VERSION ""

NS_ :

BS_:

BU_: XXX

BO_ 1665 NEW_MSG_1: 8 XXX

BO_ 545 NEW_MSG_2: 8 XXX

BO_ 261 NEW_MSG_3: 8 XXX
 SG_ NEW_SIGNAL_1 : 15|2@0+ (1,0) [0|3] "" XXX
 SG_ NEW_SIGNAL_2 : 0|4@1+ (1,0) [0|15] "" XXX

BO_ 35 C3_Steering_Column_msg1: 8 XXX

BO_ 133 C2_Transmission_Control_msg1: 8 XXX

BO_ 55 C2_Transmission_Control_msg4: 8 XXX

BO_ 119 C8_Body_Control_msg62: 2 XXX

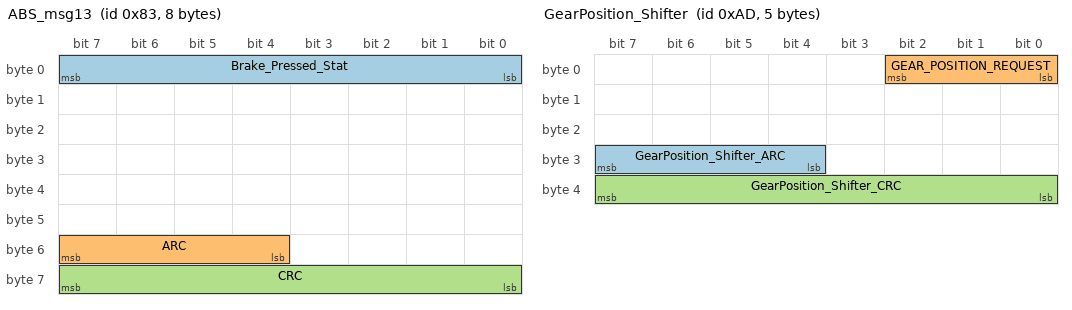
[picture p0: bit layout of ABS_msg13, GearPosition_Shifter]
BO_ 131 ABS_msg13: 8 XXX
 SG_ Brake_Pressed_Stat : 7|8@0+ (1,0) [0|255] "" XXX
 SG_ ARC : 55|4@0+ (1,0) [0|15] "" XXX
 SG_ CRC : 63|8@0+ (1,0) [0|255] "" XXX

BO_ 177 C3_Steering_Column_msg2: 3 XXX

BO_ 213 C5_Antilock_braking_system_msg4: 8 XXX

BO_ 808 C8_Body_Control_msg49: 8 XXX
 SG_ NEW_SIGNAL_1 : 5|20@0+ (1,0) [0|1048575] "" XXX

BO_ 173 GearPosition_Shifter: 5 XXX
 SG_ GearPosition_Shifter_ARC : 31|4@0+ (1,0) [0|15] "" XXX
 SG_ GEAR_POSITION_REQUEST : 0|3@1+ (1,0) [0|7] "" XXX
 SG_ GearPosition_Shifter_CRC : 32|8@1+ (1,0) [0|255] "" XXX

BO_ 1033 C6_Electronic_Shifter_msg1: 8 XXX

BO_ 973 C2_Cluster_msg1: 8 XXX

BO_ 906 C8_Body_Control_msg1: 8 XXX

BO_ 792 C3_Steering_Column_msg3: 8 XXX

BO_ 1059 C3_Steering_Column_msg4: 8 XXX

BO_ 938 C2_Cluster_msg2: 8 XXX

BO_ 673 C2_Cluster_msg3: 8 XXX

BO_ 635 C2_Cluster_msg4: 8 XXX

BO_ 939 C2_Cluster_msg5: 8 XXX

BO_ 634 C2_Cluster_msg6: 8 XXX

BO_ 940 C2_Cluster_msg7: 8 XXX

BO_ 941 C2_Cluster_msg8: 8 XXX

BO_ 942 C2_Cluster_msg9: 8 XXX

BO_ 943 C2_Cluster_msg10: 8 XXX

BO_ 503 C2_Cluster_msg11: 8 XXX

BO_ 1026 C2_Cluster_msg12: 8 XXX

BO_ 754 C2_Cluster_msg13: 8 XXX

BO_ 464 C7_Occupant_Restraint_Controller_msg1: 8 XXX

BO_ 43 C7_Occupant_Restraint_Controller_msg1: 8 XXX

BO_ 996 C8_Body_Control_msg2: 8 XXX

BO_ 910 C8_Body_Control_msg3: 8 XXX

BO_ 995 C8_Body_Control_msg5: 8 XXX

BO_ 926 C8_Body_Control_msg6: 3 XXX

BO_ 1002 C8_Body_Control_msg7: 8 XXX

BO_ 1008 C8_Body_Control_msg9: 8 XXX

BO_ 1098 C8_Body_Control_msg10: 8 XXX

BO_ 948 C8_Body_Control_msg11: 8 XXX

BO_ 962 C8_Body_Control_msg12: 8 XXX

BO_ 1009 C8_Body_Control_msg13: 8 XXX

BO_ 1100 C8_Body_Control_msg14: 8 XXX

BO_ 1010 C8_Body_Control_msg15: 8 XXX

BO_ 1015 C8_Body_Control_msg16: 8 XXX

BO_ 984 C8_Body_Control_msg17: 8 XXX

BO_ 1011 C8_Body_Control_msg18: 8 XXX

BO_ 983 C8_Body_Control_msg19: 8 XXX

BO_ 1012 C8_Body_Control_msg20: 8 XXX

BO_ 1013 C8_Body_Control_msg21: 8 XXX

BO_ 981 C8_Body_Control_msg25: 8 XXX

BO_ 979 C8_Body_Control_msg23: 8 XXX

BO_ 980 C8_Body_Control_msg24: 8 XXX

BO_ 982 C8_Body_Control_msg25: 8 XXX

BO_ 1014 C8_Body_Control_msg26: 8 XXX

BO_ 706 C8_Body_Control_msg27: 8 XXX

BO_ 709 C8_Body_Control_msg28: 8 XXX

BO_ 710 C8_Body_Control_msg29: 8 XXX

BO_ 897 C8_Body_Control_msg30: 8 XXX

BO_ 613 C8_Body_Control_msg31: 8 XXX

BO_ 937 C8_Body_Control_msg32: 8 XXX

BO_ 607 C8_Body_Control_msg33: 8 XXX

BO_ 605 C8_Body_Control_msg34: 8 XXX

BO_ 1003 C8_Body_Control_msg35: 8 XXX

BO_ 689 C8_Body_Control_msg36: 4 XXX

BO_ 609 C8_Body_Control_msg37: 8 XXX

BO_ 663 C8_Body_Control_msg38: 8 XXX

BO_ 557 C8_Body_Control_msg39: 8 XXX

BO_ 641 C8_Body_Control_msg36: 8 XXX

BO_ 856 C8_Body_Control_msg41: 8 XXX

BO_ 643 C8_Body_Control_msg42: 8 XXX

BO_ 860 C8_Body_Control_msg43: 8 XXX

BO_ 969 C8_Body_Control_msg44: 4 XXX

BO_ 657 C8_Body_Control_msg45: 8 XXX

BO_ 649 C8_Body_Control_msg46: 8 XXX

BO_ 650 C8_Body_Control_msg47: 8 XXX

BO_ 623 C8_Body_Control_msg1: 8 XXX

BO_ 848 C8_Body_Control_msg50: 8 XXX

BO_ 818 C8_Body_Control_msg51: 8 XXX

BO_ 752 C8_Body_Control_msg52: 2 XXX

BO_ 1000 C8_Body_Control_msg53: 8 XXX

BO_ 456 C8_Body_Control_msg54: 8 XXX

BO_ 560 C8_Body_Control_msg55: 8 XXX

BO_ 584 C8_Body_Control_msg56: 8 XXX

BO_ 1025 C8_Body_Control_msg57: 8 XXX

BO_ 307 C8_Body_Control_msg58: 8 XXX

BO_ 299 C8_Body_Control_msg59: 8 XXX

BO_ 319 C8_Body_Control_msg60: 8 XXX

BO_ 720 C8_Body_Control_msg61: 8 XXX

BO_ 155 C8_Body_Control_msg63: 8 XXX

BO_ 656 C9_Radio_Frequency_Hub_msg1: 4 XXX

BO_ 679 C9_Radio_Frequency_Hub_msg2: 8 XXX

BO_ 773 C9_Radio_Frequency_Hub_msg3: 8 XXX

BO_ 1024 C9_Radio_Frequency_Hub_msg4: 8 XXX

BO_ 297 C9_Radio_Frequency_Hub_msg5: 4 XXX

BO_ 448 C9_Radio_Frequency_Hub_msg6: 8 XXX

BO_ 502 C10_Park_Assist_msg1: 8 XXX

BO_ 489 C10_Park_Assist_msg2: 8 XXX

BO_ 825 C10_Park_Assist_msg3: 2 XXX

BO_ 491 C10_Park_Assist_msg4: 8 XXX

BO_ 169 C10_Park_Assist_msg5: 8 XXX

BO_ 601 C12_Occupant_Classification: 8 XXX

BO_ 293 C2_Transmission_Control_msg1: 3 XXX

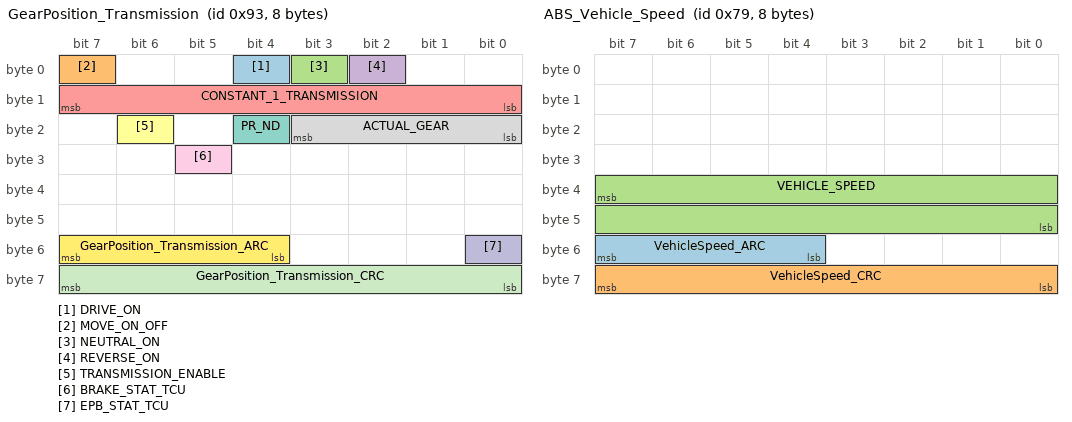
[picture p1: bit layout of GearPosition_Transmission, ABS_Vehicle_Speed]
BO_ 147 GearPosition_Transmission: 8 XXX
 SG_ DRIVE_ON : 4|1@0+ (1,0) [0|1] "" XXX
 SG_ MOVE_ON_OFF : 7|1@0+ (1,0) [0|1] "" XXX
 SG_ NEUTRAL_ON : 3|1@0+ (1,0) [0|1] "" XXX
 SG_ REVERSE_ON : 2|1@0+ (1,0) [0|1] "" XXX
 SG_ CONSTANT_1_TRANSMISSION : 15|8@0+ (1,0) [0|255] "" XXX
 SG_ TRANSMISSION_ENABLE : 22|1@0+ (1,0) [0|1] "" XXX
 SG_ PR_ND : 20|1@0+ (1,0) [0|1] "" XXX
 SG_ ACTUAL_GEAR : 16|4@1+ (1,0) [0|15] "" XXX
 SG_ BRAKE_STAT_TCU : 29|1@0+ (1,0) [0|1] "" XXX
 SG_ EPB_STAT_TCU : 48|1@0+ (1,0) [0|1] "" XXX
 SG_ GearPosition_Transmission_CRC : 63|8@0+ (1,0) [0|255] "" XXX
 SG_ GearPosition_Transmission_ARC : 55|4@0+ (1,0) [0|15] "" XXX

BO_ 149 C2_Transmission_Control_msg5: 7 XXX

BO_ 171 C2_Transmission_Control_msg6: 8 XXX

BO_ 179 C2_Transmission_Control_msg7: 8 XXX

BO_ 1050 C3_Eps_msg1: 8 XXX

BO_ 296 C3_Eps_msg1: 8 XXX

BO_ 164 C3_Eps_msg3: 8 XXX

BO_ 49 C3_Eps_msg4: 8 XXX

BO_ 875 C4_Active_Vibration_Cancellation_msg1: 2 XXX

BO_ 1031 ABS_NM_msg: 8 XXX

BO_ 421 C5_Antilock_braking_system_msg2: 8 XXX

BO_ 221 C5_Antilock_braking_system_msg3: 8 XXX

BO_ 135 C5_Antilock_braking_system_msg5: 8 XXX

BO_ 137 C5_Antilock_braking_system_msg6: 8 XXX

BO_ 167 C5_Antilock_braking_system_msg8: 8 XXX

BO_ 47 ABS_msg9: 8 XXX
 SG_ Brake_Travel : 39|16@0+ (1,0) [0|65535] "" XXX

BO_ 113 C5_Antilock_braking_system_msg10: 8 XXX

BO_ 121 ABS_Vehicle_Speed: 8 XXX
 SG_ VehicleSpeed_ARC : 55|4@0+ (1,0) [0|15] "" XXX
 SG_ VehicleSpeed_CRC : 63|8@0+ (1,0) [0|255] "" XXX
 SG_ VEHICLE_SPEED : 39|16@0+ (0.00483,0) [0|316.6] "MPH" XXX

BO_ 127 C5_Antilock_braking_system_msg12: 8 XXX

BO_ 633 ECM_msg1: 8 XXX
 SG_ Engine_Oil_Life : 15|8@0+ (1,0) [0|255] "" XXX

BO_ 347 C6_Powertrain_Control_msg2: 8 XXX

BO_ 676 C6_Powertrain_Control_msg3: 8 XXX

BO_ 343 C6_Powertrain_Control_msg4: 8 XXX

BO_ 323 C6_Powertrain_Control_msg5: 8 XXX

BO_ 317 C6_Powertrain_Control_msg6: 8 XXX

BO_ 289 C6_Powertrain_Control_msg7: 5 XXX

BO_ 993 C6_Powertrain_Control_msg8: 7 XXX

BO_ 334 C6_Powertrain_Control_msg9: 8 XXX

BO_ 129 C6_Powertrain_Control_msg10: 8 XXX

BO_ 125 C6_Powertrain_Control_msg11: 8 XXX

BO_ 311 C6_Powertrain_Control_msg12: 8 XXX

BO_ 333 C6_Powertrain_Control_msg13: 8 XXX

BO_ 181 ECM_msg14: 8 XXX
 SG_ Engine_Speed_DIS : 23|16@0+ (1,0) [0|65535] "" XXX

BO_ 295 C6_Powertrain_Control_msg15: 8 XXX

BO_ 992 C6_Powertrain_Control_msg16: 8 XXX

BO_ 53 C6_Powertrain_Control_msg17: 8 XXX

BO_ 123 ECM_msg_18: 7 XXX
 SG_ ARC : 47|4@0+ (1,0) [0|15] "" XXX

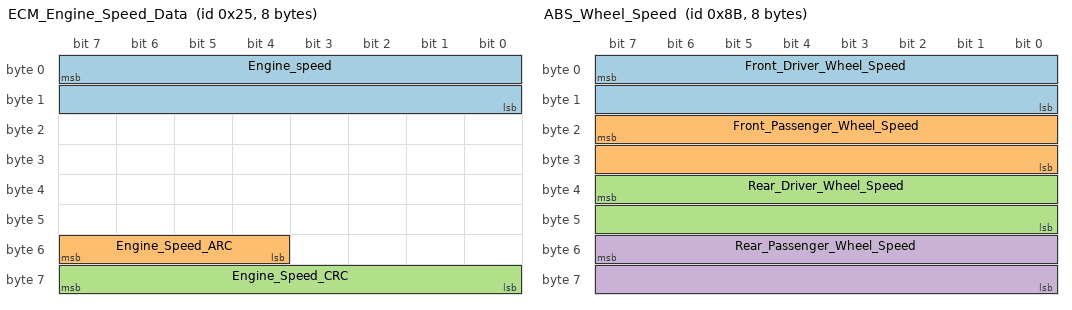
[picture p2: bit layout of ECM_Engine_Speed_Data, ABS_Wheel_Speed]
BO_ 37 ECM_Engine_Speed_Data: 8 XXX
 SG_ Engine_speed : 7|16@0+ (1,0) [0|65535] "" XXX
 SG_ Engine_Speed_ARC : 55|4@0+ (1,0) [0|15] "" XXX
 SG_ Engine_Speed_CRC : 63|8@0+ (1,0) [0|255] "" XXX

BO_ 157 C6_Powertrain_Control_msg20: 8 XXX

BO_ 39 C6_Powertrain_Control_msg21: 8 XXX

BO_ 139 ABS_Wheel_Speed: 8 XXX
 SG_ Front_Driver_Wheel_Speed : 7|16@0+ (1,0) [0|65535] "" XXX
 SG_ Front_Passenger_Wheel_Speed : 23|16@0+ (1,0) [0|65535] "" XXX
 SG_ Rear_Driver_Wheel_Speed : 39|16@0+ (1,0) [0|65535] "" XXX
 SG_ Rear_Passenger_Wheel_Speed : 55|16@0+ (1,0) [0|65535] "" XXX

BO_ 517 ECM_Immobilizer_msg: 8 XXX
 SG_ Immobilizer_Auth : 7|8@0+ (1,0) [0|255] "" XXX
